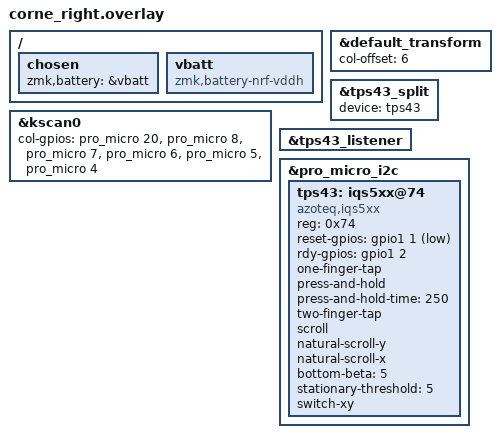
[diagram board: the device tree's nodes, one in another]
/*
 * Copyright (c) 2020 Ryan Cross
 *
 * SPDX-License-Identifier: MIT
 */

#include "corne.dtsi"

&default_transform {
    col-offset = <6>;
};


&kscan0 {
    col-gpios
        = <&pro_micro 20 GPIO_ACTIVE_HIGH>
        , <&pro_micro 8 GPIO_ACTIVE_HIGH>
        , <&pro_micro 7 GPIO_ACTIVE_HIGH>
        , <&pro_micro 6 GPIO_ACTIVE_HIGH>
        , <&pro_micro 5 GPIO_ACTIVE_HIGH>
        , <&pro_micro 4 GPIO_ACTIVE_HIGH>
        ;
};

/ {
    chosen {
        zmk,battery = &vbatt;
        /delete-property/ zephyr,display;  // 디스플레이 참조 제거
    };

    vbatt: vbatt {
        compatible = "zmk,battery-nrf-vddh";
    };
};

&tps43_split {
    device = <&tps43>;
};

&tps43_listener {
    status = "okay";
};


&pro_micro_i2c {
    status = "okay";
    
    // OLED 설정 완전 제거하고 트랙패드만 유지
    tps43: iqs5xx@74 {
        status = "okay";
        compatible = "azoteq,iqs5xx";
        reg = <0x74>;

        reset-gpios = <&gpio1 1 GPIO_ACTIVE_LOW>;
        rdy-gpios = <&gpio1 2 GPIO_ACTIVE_HIGH>;

        /*
         * Potentially non-exhaustive list of configuration options.
         * See: dts/bindings/input/azoteq,iqs5xx-common.yaml for a full list.
         */
        one-finger-tap;
        press-and-hold;
        press-and-hold-time = <250>;
        two-finger-tap;

        scroll;
        natural-scroll-y;
        natural-scroll-x;

        bottom-beta = <5>;
        stationary-threshold = <5>;

        switch-xy;
    };
};
